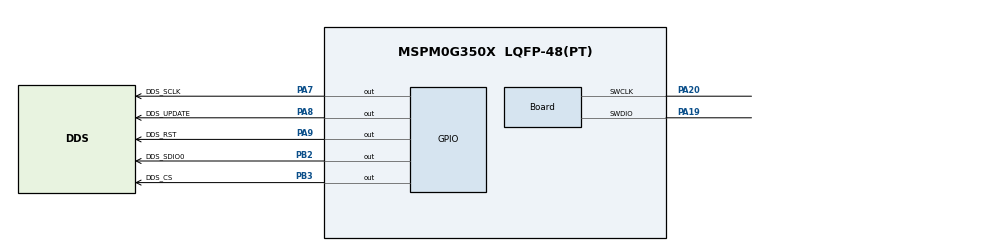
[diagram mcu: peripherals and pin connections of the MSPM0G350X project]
/**
 * These arguments were used when this file was generated. They will be automatically applied on subsequent loads
 * via the GUI or CLI. Run CLI with '--help' for additional information on how to override these arguments.
 * @cliArgs --device "MSPM0G350X" --package "LQFP-48(PT)" --part "Default" --product "mspm0_sdk@2.10.00.04"
 * @versions {"tool":"1.26.2"}
 */

/**
 * Import the modules used in this configuration.
 */
const GPIO          = scripting.addModule("/ti/driverlib/GPIO", {}, false);
const GPIO1         = GPIO.addInstance();
const SYSCTL        = scripting.addModule("/ti/driverlib/SYSCTL");
const SYSTICK       = scripting.addModule("/ti/driverlib/SYSTICK");
const ProjectConfig = scripting.addModule("/ti/project_config/ProjectConfig");

/**
 * Write custom configuration values to the imported modules.
 */
const divider9       = system.clockTree["UDIV"];
divider9.divideValue = 2;

const multiplier2         = system.clockTree["PLL_QDIV"];
multiplier2.multiplyValue = 5;   /* BUILD-3: 片内 SYSOSC 32MHz ×5 = 160MHz VCO, 输出 /2 = 80MHz (原 HFCLK 40×4) */

const mux2       = system.clockTree["CANCLKMUX"];
mux2.inputSelect = "CANCLKMUX_PLLCLK1_OUT";

const mux8       = system.clockTree["HSCLKMUX"];
mux8.inputSelect = "HSCLKMUX_SYSPLL0";

/* BUILD-3: SYSPLL 改用片内 SYSOSC(32MHz, 任何板子都有), 去除对 PA6 外部 40MHz 时钟的依赖.
 * 原配置依赖 HFCLKEXT(PA6 灌入 40MHz), 番茄派若无该外部时钟则 SYSCFG_DL_init 卡死在等 PLL 锁定. */
const mux12       = system.clockTree["SYSPLLMUX"];
mux12.inputSelect = "SYSPLLMUX_SYSOSC";

GPIO1.$name                          = "GPIO_DDS";
GPIO1.associatedPins.create(5);
GPIO1.associatedPins[0].$name        = "DDS_SCLK";
GPIO1.associatedPins[0].assignedPort = "PORTA";
GPIO1.associatedPins[0].assignedPin  = "7";
GPIO1.associatedPins[0].pin.$assign  = "PA7";
GPIO1.associatedPins[1].$name        = "DDS_SDIO0";
GPIO1.associatedPins[1].assignedPort = "PORTB";
GPIO1.associatedPins[1].assignedPin  = "2";
GPIO1.associatedPins[1].pin.$assign  = "PB2";
GPIO1.associatedPins[2].$name        = "DDS_CS";
GPIO1.associatedPins[2].assignedPort = "PORTB";
GPIO1.associatedPins[2].assignedPin  = "3";
GPIO1.associatedPins[2].pin.$assign  = "PB3";
GPIO1.associatedPins[3].$name        = "DDS_UPDATE";
GPIO1.associatedPins[3].assignedPort = "PORTA";
GPIO1.associatedPins[3].assignedPin  = "8";
GPIO1.associatedPins[3].pin.$assign  = "PA8";
GPIO1.associatedPins[4].$name        = "DDS_RST";
GPIO1.associatedPins[4].assignedPort = "PORTA";
GPIO1.associatedPins[4].assignedPin  = "9";
GPIO1.associatedPins[4].pin.$assign  = "PA9";

const Board                       = scripting.addModule("/ti/driverlib/Board", {}, false);
Board.peripheral.$assign          = "DEBUGSS";
Board.peripheral.swclkPin.$assign = "PA20";
Board.peripheral.swdioPin.$assign = "PA19";

SYSCTL.clockTreeEn = true;

SYSTICK.periodEnable    = true;
SYSTICK.period          = 80000;
SYSTICK.interruptEnable = true;
SYSTICK.systickEnable   = true;

ProjectConfig.deviceSpin = "MSPM0G3507";
scripting.suppress("Migrating requires going through the Switch Board or Device menu in the Device View section\\.", ProjectConfig, "deviceSpin");
